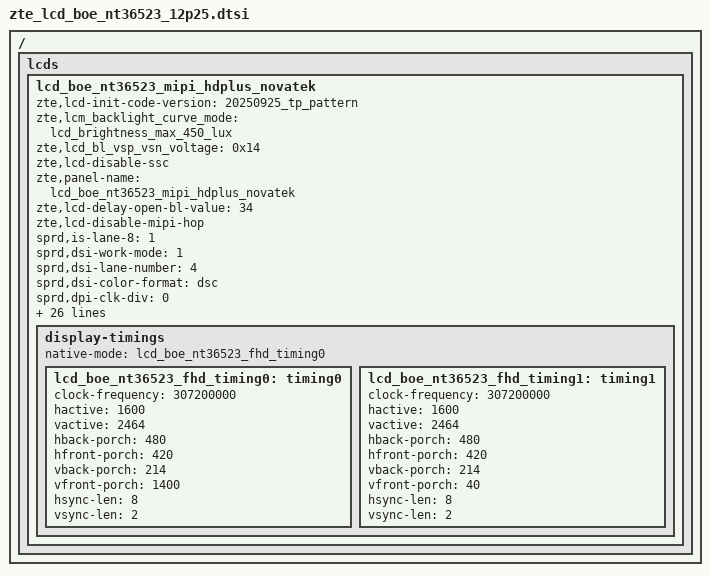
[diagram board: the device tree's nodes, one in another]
/ {
	fragment {
		target-path = "/";
		__overlay__ {
			lcds {
				lcd_boe_nt36523_mipi_hdplus_novatek: lcd_boe_nt36523_mipi_hdplus_novatek {
					zte,lcd-init-code-version = "20250925_tp_pattern";
					zte,lcm_backlight_curve_mode = "lcd_brightness_max_450_lux";
					zte,lcd_bl_vsp_vsn_voltage = <0x14>;
					zte,lcd-disable-ssc;
					zte,panel-name = "lcd_boe_nt36523_mipi_hdplus_novatek";
					zte,lcd-delay-open-bl-value = <34>;
					zte,lcd-disable-mipi-hop;

					sprd,is-lane-8 = <1>;
					sprd,dsi-work-mode = <1>;
					sprd,dsi-lane-number = <4>;
					sprd,dsi-color-format = "dsc";
					sprd,dpi-clk-div = <0>;
					//sprd,video-lp-cmd-enable = <1>;
					//sprd,video-lp-en-mode = <3>;
					//sprd,dsi-non-continuous-clock;
					//sprd,hporch-lp-disable = <1>;
					sprd,vrr-enabled;
					sprd,vrr-max-layers = <3>;
					sprd,slice-width = <800>;
					sprd,slice-height = <32>;
					sprd,output-bpc = <8>;
					sprd,dsc-enable = <1>;
					sprd,dual-dsi-enable = <1>;

					sprd,phy-bit-clock = <952600>;
					sprd,phy-escape-clock = <20000>;/* kHz */

					sprd,width-mm = <16944>;
					sprd,height-mm = <26094>;

					sprd,esd-check-enable = <1>;/* 0:close , 1:open */
					sprd,esd-check-mode = <1>;/* 0:REG ,1:TE  */
					sprd,esd-check-period = <2000>;
					sprd,esd-check-register = <0x0A>;
					sprd,esd-check-value = <0x9C>;

					sprd,dphy-taget-val = <5>;

					sprd,reset-on-sequence = <0 10>, <1 10>, <0 10>, <1 20>;
					sprd,reset-off-sequence = <1 20>;

					sprd,use-gen-write;
					sprd,initial-command = [
39 00 00 02 FF 20 
39 00 00 02 FB 01 
//pump level VGH=3X,VGL=2.5X
39 00 00 02 05 C9 
39 00 00 02 07 91 
39 00 00 02 08 46 
39 00 00 02 0D 63 
39 00 00 02 0E A5
39 00 00 02 0F 64 
39 00 00 02 58 43 
39 00 00 02 69 DD 
39 00 00 02 6D CC 
39 00 00 02 6E 00 
39 00 00 02 94 C0 
39 00 00 02 95 04 
39 00 00 02 96 0E 
39 00 00 02 FF 24 
39 00 00 02 FB 01 
39 00 00 02 00 08 
39 00 00 02 01 04 
39 00 00 02 02 26 
39 00 00 02 03 26 
39 00 00 02 04 1C 
39 00 00 02 05 1D 
39 00 00 02 06 13 
39 00 00 02 07 13 
39 00 00 02 08 12 
39 00 00 02 09 12 
39 00 00 02 0A 11 
39 00 00 02 0B 11 
39 00 00 02 0C 10 
39 00 00 02 0D 10 
39 00 00 02 0E 0F 
39 00 00 02 0F 0F 
39 00 00 02 10 0E 
39 00 00 02 11 0E 
39 00 00 02 12 0D 
39 00 00 02 13 0D 
39 00 00 02 14 0C 
39 00 00 02 15 0C 
39 00 00 02 16 08 
39 00 00 02 17 04 
39 00 00 02 18 26 
39 00 00 02 19 26 
39 00 00 02 1A 1C 
39 00 00 02 1B 1D 
39 00 00 02 1C 13 
39 00 00 02 1D 13 
39 00 00 02 1E 12 
39 00 00 02 1F 12 
39 00 00 02 20 11 
39 00 00 02 21 11 
39 00 00 02 22 10 
39 00 00 02 23 10 
39 00 00 02 24 0F 
39 00 00 02 25 0F 
39 00 00 02 26 0E 
39 00 00 02 27 0E 
39 00 00 02 28 0D 
39 00 00 02 29 0D 
39 00 00 02 2A 0C 
39 00 00 02 2B 0C 
//STV
39 00 00 02 2D 20 
39 00 00 02 2F 5F 
39 00 00 02 30 11 
39 00 00 02 37 88 
39 00 00 02 3A 09 
39 00 00 02 3B 41 
39 00 00 02 3D 92 
//RESET
39 00 00 02 3F 08 
39 00 00 02 47 88 
39 00 00 02 4A 09 
39 00 00 02 4B 41 
39 00 00 02 4C 91 
//GCK
39 00 00 02 50 87 
39 00 00 03 55 82 03 
39 00 00 02 56 08 
39 00 00 02 59 30 
39 00 00 02 5A 55 
39 00 00 02 5B 43 
39 00 00 02 5C 88 		  
39 00 00 03 5E 00 1D 
39 00 00 02 60 C8 
39 00 00 02 61 A0 
39 00 00 02 63 90 
//POL
39 00 00 02 7E 20 
39 00 00 02 7F 96 
39 00 00 02 92 65 
39 00 00 03 93 28 00 
39 00 00 03 94 D8 00 
39 00 00 02 99 40
39 00 00 0d B6 05 00 05 00 00 00 05 05 05 05 05 05
39 00 00 02 BB 80 
39 00 00 06 BC 00 00 40 20 00 
//VSSA
39 00 00 04 C2 C7 00 08
39 00 00 02 DB 0F 
39 00 00 02 DC 4D 
39 00 00 02 DF 0F 
39 00 00 02 E0 4D 
39 00 00 02 E1 0F 
39 00 00 02 E2 4D 
39 00 00 02 E3 0F 
39 00 00 02 E4 4D 
39 00 00 02 E5 0F 
39 00 00 02 E6 4D 
39 00 00 02 E9 0F 
39 00 00 02 EA 4D 
39 00 00 02 EB 0F 
39 00 00 02 EC 80
39 00 00 02 EE 4D 
39 00 00 02 EF 0F 
39 00 00 02 F0 4D 
39 00 00 02 FF 25 
39 00 00 02 FB 01 
39 00 00 02 05 04 
39 00 00 02 13 01 
39 00 00 02 14 B9 
39 00 00 02 15 02 
39 00 00 02 16 4C 
39 00 00 02 1B 55 
39 00 00 02 1F 55 
39 00 00 02 20 43 
39 00 00 02 26 55 
39 00 00 02 27 43 
39 00 00 02 33 55 
39 00 00 02 34 43 
39 00 00 02 3F 00 
39 00 00 02 40 00 
39 00 00 02 44 09 
39 00 00 02 45 41 
39 00 00 02 46 09 
39 00 00 02 47 41 
39 00 00 02 48 55 
39 00 00 02 49 43 
39 00 00 02 50 55 
39 00 00 02 51 43 
39 00 00 02 5B 00 
39 00 00 02 5D 09 
39 00 00 02 5E 41 
39 00 00 02 5F 09 
39 00 00 02 60 41 
39 00 00 02 61 55 
39 00 00 02 62 43 
39 00 00 02 68 00 
39 00 00 02 C5 17 
39 00 00 02 C6 11 
39 00 00 02 DB 01 
39 00 00 02 DC 5B 
39 00 00 02 DD 01 
39 00 00 02 DE CF 
39 00 00 02 FF 26 
39 00 00 02 FB 01 
39 00 00 02 00 81 
39 00 00 02 04 7D 
39 00 00 02 06 41 
39 00 00 02 0A F5 
39 00 00 02 0C 04 
39 00 00 02 0D 00 
39 00 00 02 0F 09 
39 00 00 02 11 00 
39 00 00 02 12 51 
39 00 00 02 13 ED 
39 00 00 02 14 ED 
39 00 00 02 16 91 
39 00 00 02 19 1B 
39 00 00 02 1A 73 
39 00 00 02 1B 19 
39 00 00 02 1C 7A 
39 00 00 02 1E 65 
39 00 00 02 1F 65 
39 00 00 02 24 02 
39 00 00 02 25 65 
39 00 00 02 26 26 
39 00 00 02 2A 1B 
39 00 00 02 2B 73 
39 00 00 02 2F 04 
39 00 00 02 30 65 
39 00 00 02 32 65 
39 00 00 02 33 32
39 00 00 02 34 33
39 00 00 02 35 66 
39 00 00 02 36 66 
39 00 00 02 37 66 
39 00 00 02 38 06 
39 00 00 02 39 02 
39 00 00 02 3A 65 
39 00 00 02 3B 06 
39 00 00 02 40 5D 
39 00 00 02 41 5D 
39 00 00 02 42 5D 
39 00 00 02 43 02 
39 00 00 02 44 5D 
39 00 00 02 45 04 
39 00 00 02 46 5D 
39 00 00 02 48 5D 
39 00 00 02 49 02 
39 00 00 02 4A 5D 
39 00 00 02 4B 06 
39 00 00 02 4D 09 
39 00 00 02 4E 4B 
39 00 00 02 4F 09 
39 00 00 02 50 4B 
39 00 00 02 51 5F 
39 00 00 02 52 4B 
39 00 00 02 56 5F 
39 00 00 02 58 4B 
39 00 00 02 5B 5F 
39 00 00 02 5C 4B 
39 00 00 02 60 5F 
39 00 00 02 61 4B 
39 00 00 02 64 5F 
39 00 00 02 65 4B 
39 00 00 02 69 5F 
39 00 00 02 6A 4B 
39 00 00 02 6E 09 
39 00 00 02 6F 4B 
39 00 00 02 70 09 
39 00 00 02 71 4B 
39 00 00 02 72 5F 
39 00 00 02 73 4B 
39 00 00 02 80 99 
39 00 00 05 82 00 55 55 55 
39 00 00 02 8B 7D 
39 00 00 02 8C 0E 
39 00 00 02 8D 08 
39 00 00 02 8F 00 
39 00 00 02 91 00 
39 00 00 02 92 50 
39 00 00 02 93 83 
39 00 00 02 94 A5 
39 00 00 02 96 10 
39 00 00 02 99 1B 
39 00 00 02 9A BF 
39 00 00 02 9B 19 
39 00 00 02 9C C4 
39 00 00 02 9D 1B 
39 00 00 02 9E BF 
39 00 00 02 A7 01
39 00 00 03 A9 EE 01 
39 00 00 03 AA EF 01 
39 00 00 03 AB F0 01 
39 00 00 03 AC F1 01 
39 00 00 03 AD F2 01 
39 00 00 03 AE F3 01 
39 00 00 03 AF F4 01 
39 00 00 03 B0 F5 01 
39 00 00 03 B1 F6 01 
39 00 00 03 B2 F7 01 
39 00 00 03 B3 F8 01 
39 00 00 03 B4 F9 01 
39 00 00 03 B5 FA 01 
39 00 00 03 B6 FB 01 
39 00 00 03 B7 FC 01 
39 00 00 03 B8 FD 01 
39 00 00 03 B9 FE 01 
39 00 00 03 BA FF 01 
39 00 00 03 BB 00 02 
39 00 00 03 BC 01 02 
39 00 00 03 BD 02 02 
39 00 00 03 BE 03 02 
39 00 00 03 BF 04 02 
39 00 00 03 C0 05 02 
39 00 00 03 C1 06 02 
39 00 00 03 C2 07 02 
39 00 00 03 C3 08 02 
39 00 00 03 C4 09 02 
39 00 00 03 C5 0A 02 
39 00 00 02 C9 1E 
39 00 00 02 CA 6E 
39 00 00 02 CB 9E 
39 00 00 03 CD 37 7F
39 00 00 03 CE 35 7F
39 00 00 04 CF 01 00 2A
39 00 00 02 D2 AF
39 00 00 02 D6 89
39 00 00 02 D7 8F
39 00 00 02 D8 95
39 00 00 02 D9 9B
39 00 00 02 DA 85
39 00 00 02 DB 8B
39 00 00 02 DC 91
39 00 00 02 DD 97
39 00 00 02 DE 9D
39 00 00 02 DF 84
39 00 00 02 E0 8A
39 00 00 02 E1 90
39 00 00 02 E2 96
39 00 00 02 E3 9C
39 00 00 02 E4 86
39 00 00 02 E5 8C
39 00 00 02 E6 92
39 00 00 02 E7 98
39 00 00 02 E8 9E
39 00 00 02 E9 88
39 00 00 02 EA 8E
39 00 00 02 EB 94
39 00 00 02 EC 9A
39 00 00 02 ED A0
39 00 00 02 EE 87
39 00 00 02 EF 8D
39 00 00 02 F0 93
39 00 00 02 F1 99
39 00 00 02 F2 9F
39 00 00 02 F7 04

39 00 00 02 FF 27
39 00 00 02 FB 01
39 00 00 02 13 06
39 00 00 02 58 80
39 00 00 02 59 00
39 00 00 02 5A 00
39 00 00 02 5B B9
39 00 00 02 5C 01
39 00 00 02 5D 82
39 00 00 02 5E 00
39 00 00 02 5F 0A
39 00 00 02 60 8C
39 00 00 02 61 C4
39 00 00 02 62 C5
39 00 00 02 63 00
39 00 00 02 64 00
39 00 00 02 65 C3
39 00 00 02 66 C5
39 00 00 02 67 00
39 00 00 02 68 00
39 00 00 02 78 80
39 00 00 02 79 00
39 00 00 02 7A 00
39 00 00 02 7B D7
39 00 00 02 7C 00
39 00 00 02 7D 2B
39 00 00 02 7E 00
39 00 00 02 7F 0A 
39 00 00 02 80 8C 
39 00 00 02 81 5E 
39 00 00 02 82 87 
39 00 00 02 83 00 
39 00 00 02 84 00
39 00 00 02 85 5C 
39 00 00 02 86 87 
39 00 00 02 87 00 
39 00 00 02 88 00
39 00 00 02 D0 13 
39 00 00 02 D1 54 
39 00 00 02 DE 43 
39 00 00 02 DF 02 
//CMD2,Page10 
39 00 00 02 FF 2A 
39 00 00 02 FB 01 
39 00 00 02 22 0F 
//FR0
39 00 00 02 24 00 
39 00 00 02 25 5D 
39 00 00 02 27 00 
39 00 00 02 28 28 
39 00 00 02 29 00 
39 00 00 02 2A 28 
39 00 00 02 2B 00 
39 00 00 02 2D 28 
39 00 00 02 2F 00 
39 00 00 02 30 65 
39 00 00 02 32 00 
39 00 00 02 33 28 
39 00 00 02 34 00 
39 00 00 02 35 28 
39 00 00 02 36 00 
39 00 00 02 37 28 
//power sequence
39 00 00 02 64 9E 
39 00 00 02 67 96 
39 00 00 02 6A 96 
39 00 00 02 70 90 
39 00 00 02 7F 96 
39 00 00 02 88 16 
39 00 00 02 99 95 
39 00 00 02 9A 06 
39 00 00 02 9B 00 
//abnormal off 
39 00 00 02 A2 FF 
39 00 00 02 A3 FF 
39 00 00 02 A4 FF 
39 00 00 02 A5 FF 
39 00 00 02 A6 08 
39 00 00 0a B9 18 00 C7 00 67 9F EB 70 40
39 00 00 03 BC 33 03 
//AC
39 00 00 02 E8 00 
//osc trim
39 00 00 02 F4 95 
39 00 00 02 F5 06 
39 00 00 02 F6 00 
//osc trim
39 00 00 02 FF F0 
39 00 00 02 FB 01 
39 00 00 02 24 02 	
//PG
//CMD2_Page0
39 00 00 02 FF 20 
39 00 00 02 FB 01
//R(+)
39 00 00 11 B0 00 60 00 6B 00 7E 00 91 00 A2 00 B1 00 C0 00 CD
39 00 00 11 B1 00 DA 01 08 01 2C 01 68 01 96 01 E3 02 1F 02 21
39 00 00 11 B2 02 5E 02 A6 02 D4 03 0E 03 34 03 63 03 71 03 81
39 00 00 0d B3 03 93 03 A6 03 BB 03 D7 03 ED 03 FF
//G(+)
39 00 00 11 B4 00 60 00 6B 00 7E 00 91 00 A2 00 B1 00 C0 00 CD
39 00 00 11 B5 00 DA 01 08 01 2C 01 68 01 96 01 E3 02 1F 02 21
39 00 00 11 B6 02 5E 02 A6 02 D4 03 0E 03 34 03 63 03 71 03 81
39 00 00 0d B7 03 93 03 A6 03 BB 03 D7 03 ED 03 FF
//B(+)
39 00 00 11 B8 00 60 00 6B 00 7E 00 91 00 A2 00 B1 00 C0 00 CD
39 00 00 11 B9 00 DA 01 08 01 2C 01 68 01 96 01 E3 02 1F 02 21
39 00 00 11 BA 02 5E 02 A6 02 D4 03 0E 03 34 03 63 03 71 03 81
39 00 00 0d BB 03 93 03 A6 03 BB 03 D7 03 ED 03 FF
//R+C1
39 00 00 02 C6 52
39 00 00 02 C7 30
39 00 00 02 C8 41
39 00 00 02 C9 20
39 00 00 02 CA 21
//R-C1
39 00 00 02 CB 52
39 00 00 02 CC 30
39 00 00 02 CD 41
39 00 00 02 CE 20
39 00 00 02 CF 21
//G+C1
39 00 00 02 D0 52
39 00 00 02 D1 30
39 00 00 02 D2 41
39 00 00 02 D3 20
39 00 00 02 D4 21
//G-C1
39 00 00 02 D5 52
39 00 00 02 D6 30
39 00 00 02 D7 41
39 00 00 02 D8 20
39 00 00 02 D9 21
//B+C1
39 00 00 02 DA 52
39 00 00 02 DB 30
39 00 00 02 DC 41
39 00 00 02 DD 20
39 00 00 02 DE 21
//B-C1
39 00 00 02 DF 52
39 00 00 02 E0 30
39 00 00 02 E1 41
39 00 00 02 E2 20
39 00 00 02 E3 21
//CMD2_Page1
39 00 00 02 FF 21 
39 00 00 02 FB 01 
//R(-)
39 00 00 11 B0 00 58 00 63 00 76 00 89 00 9A 00 A9 00 B8 00 C5
39 00 00 11 B1 00 D2 01 00 01 24 01 60 01 8E 01 DB 02 17 02 19
39 00 00 11 B2 02 56 02 9E 02 CC 03 06 03 2C 03 5B 03 69 03 79
39 00 00 0d B3 03 8B 03 9E 03 B3 03 CF 03 E5 03 F7
//G(-)
39 00 00 11 B4 00 58 00 63 00 76 00 89 00 9A 00 A9 00 B8 00 C5
39 00 00 11 B5 00 D2 01 00 01 24 01 60 01 8E 01 DB 02 17 02 19
39 00 00 11 B6 02 56 02 9E 02 CC 03 06 03 2C 03 5B 03 69 03 79
39 00 00 0d B7 03 8B 03 9E 03 B3 03 CF 03 E5 03 F7
//B(-)
39 00 00 11 B8 00 58 00 63 00 76 00 89 00 9A 00 A9 00 B8 00 C5
39 00 00 11 B9 00 D2 01 00 01 24 01 60 01 8E 01 DB 02 17 02 19
39 00 00 11 BA 02 56 02 9E 02 CC 03 06 03 2C 03 5B 03 69 03 79
39 00 00 0d BB 03 8B 03 9E 03 B3 03 CF 03 E5 03 F7
39 00 00 02 ff 27 /* esd */
39 00 00 02 fb 01
39 00 00 02 d0 03
39 00 00 02 d1 55
39 00 00 02 d2 30
39 00 00 02 FF 10 
39 00 00 02 FB 01 
39 00 00 07 3B 03 D8 28 04 04 00 
39 00 00 02 90 03 
39 00 00 11 91 89 28 00 20 C2 00 02 91 03 b0 00 0b 03 19 02 21
39 00 00 03 92 10 E0 
//TB-90-切换90Hz
39 00 00 02 B2 80
39 00 00 02 B3 11 
39 00 00 02 35 00
05 64 00 01 11
05 14 00 01 29
					];

					sprd,sleep-in-command = [
						39 05 00 02 28 00
						39 78 00 02 10 00
						];
					sprd,sleep-out-command = [
						05 78 00 01 11
						05 14 00 01 29
						];
					display-timings {
						native-mode = <&lcd_boe_nt36523_fhd_timing0>;
						lcd_boe_nt36523_fhd_timing0: timing0 {
							clock-frequency = <307200000>;
							hactive = <1600>;
							vactive = <2464>;
							hback-porch = <480>;
							hfront-porch = <420>;
							vback-porch = <214>;
							vfront-porch = <1400>;/* 60hz:1400 90hz:40 */
							hsync-len = <8>;
							vsync-len = <2>;
						};
						lcd_boe_nt36523_fhd_timing1: timing1 {
							clock-frequency = <307200000>;
							hactive = <1600>;
							vactive = <2464>;
							hback-porch = <480>;
							hfront-porch = <420>;
							vback-porch = <214>;
							vfront-porch = <40>;
							hsync-len = <8>;
							vsync-len = <2>;
						};
					};
				};
			};
		};
	};
};
